# GD32F5HC register map
File version: 1.0
CPU: CM33 r0p4, little endian, MPU, FPU, 4 interrupt priority bits
Registers are 32-bit, read-write, reset 0x0 unless marked. A register's access mark holds for its fields unless they carry their own. Offsets are from the block's base; [hi:lo] are bit positions; {n}, {i} and the like mark numbered series.

## SQPI — Serial/Quad Parallel Interface
Base 0x40025400
Same registers: SEC_SQPI 0x50025400
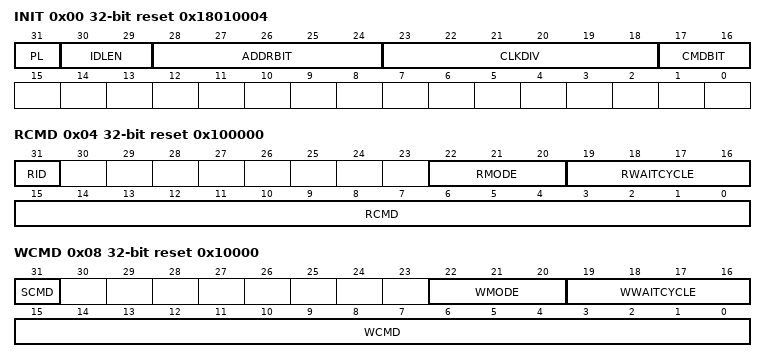
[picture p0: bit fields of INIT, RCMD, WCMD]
0x00 INIT reset 0x18010004 — SQPI Initial Register
  [31] PL — Read data sample polarity.
  [30:29] IDLEN — SQPI controller external memory ID length
  [28:24] ADDRBIT — Bit number of SPI PSRAM address phase.
  [23:18] CLKDIV — Clock divider for SQPI output clock
  [17:16] CMDBIT — Bit number of SQPI controller command phase
0x04 RCMD reset 0x100000 — SQPI Read Command Register
  [31] RID — Send read ID command
  [22:20] RMODE — SQPI controller read command mode
  [19:16] RWAITCYCLE — SQPI read command waitcycle number after address phase
  [15:0] RCMD — SQPI read command for AHB read transfer
0x08 WCMD reset 0x10000 — Write Command Register
  [31] SCMD — Send special command
  [22:20] WMODE — SQPI controller write command mode
  [19:16] WWAITCYCLE — SQPI write command waitcycle number after address phase
  [15:0] WCMD — SQPI write command for AHB write transfer
0x0C IDL ro — ID Low Register
  [31:0] IDL — ID Low Data saved for SQPI Read ID Command
0x10 IDH ro — ID High Register
  [31:0] IDH — ID High Data saved for SQPI read ID command

## SYSCFG — System configuration controller
Base 0x40013800
Same registers: SEC_SYSCFG 0x50013800
0x00 CFG0 — Configuration register 0
  [1:0] BOOT_MODE
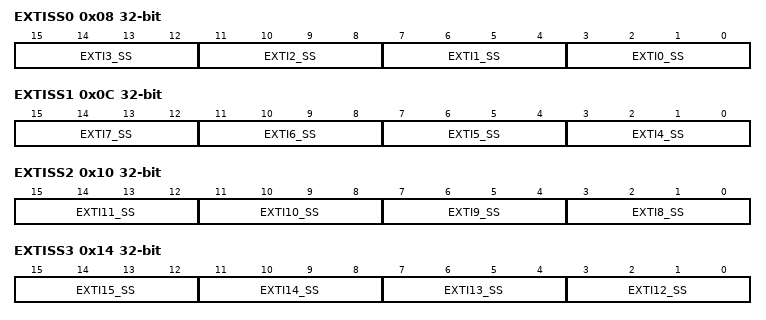
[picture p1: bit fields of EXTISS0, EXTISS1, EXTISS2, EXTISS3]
0x08 EXTISS0 — EXTI sources selection register 0
  [4n+3:4n] EXTI{n}_SS (n=0..3) — EXTI {n} sources selection
0x0C EXTISS1 — EXTI sources selection register 1
  [4n-13:4n-16] EXTI{n}_SS (n=4..7) — EXTI {n} sources selection
0x10 EXTISS2 — EXTI sources selection register 2
  [4n-29:4n-32] EXTI{n}_SS (n=8..11) — EXTI {n} sources selection
0x14 EXTISS3 — EXTI sources selection register 3
  [4n-45:4n-48] EXTI{n}_SS (n=12..15) — EXTI {n} sources selection
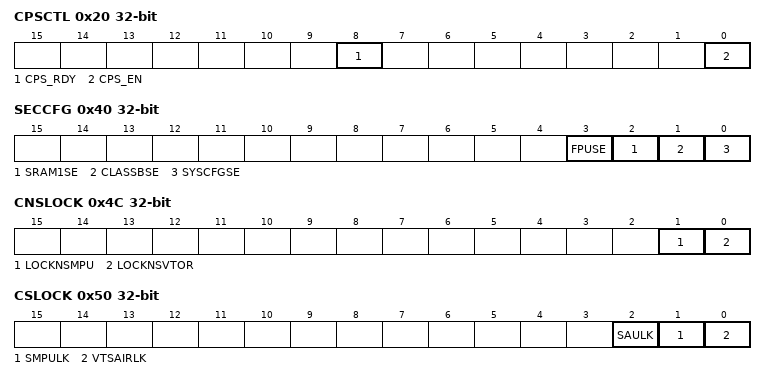
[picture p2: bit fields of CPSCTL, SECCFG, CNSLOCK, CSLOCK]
0x20 CPSCTL access per field — I/O compensation control register
  [8] CPS_RDY ro — I/O compensation cell is ready or not
  [0] CPS_EN rw — I/O compensation cell enable
0x40 SECCFG — SYSCFG secure configuration register
  [3] FPUSE — FPU security
  [2] SRAM1SE — SRAM1 security
  [1] CLASSBSE — ClassB security
  [0] SYSCFGSE — SYSCFG clock control security
0x48 FPUINTMSK reset 0x1F — FPU interrupt mask register
  [5:0] FPU_IE — Floating point unit interrupts enable bits
0x4C CNSLOCK — SYSCFG CPU non-secure lock register
  [1] LOCKNSMPU — Non-secure MPU registers lock
  [0] LOCKNSVTOR — VTOR_NS register lock
0x50 CSLOCK — SYSCFG CPU secure lock register
  [2] SAULK — SAU registers lock
  [1] SMPULK — Secure MPU registers lock
  [0] VTSAIRLK — VTOR_S register and AIRCR register bits lock
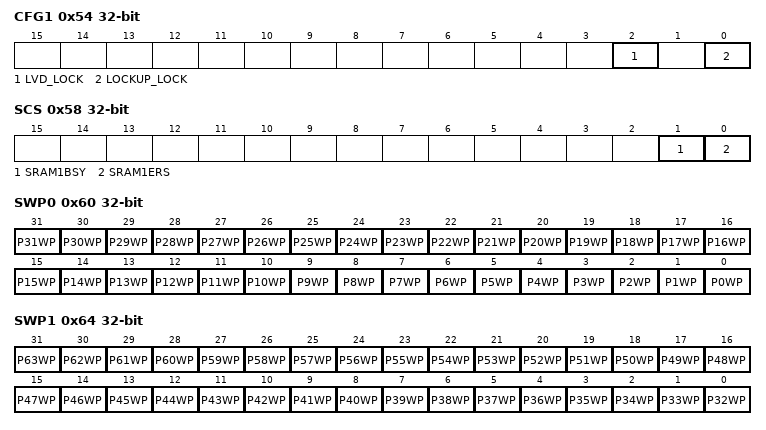
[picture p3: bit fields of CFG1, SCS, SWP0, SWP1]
0x54 CFG1 — SYSCFG configuration register 1
  [2] LVD_LOCK — LVD lock enable bit
  [0] LOCKUP_LOCK — Cortex M33 LOCKUP (hardfault) output enable bit
0x58 SCS access per field — SYSCFG SRAM1 control and status register
  [1] SRAM1BSY ro — SRAM1 busy by erase operation
  [0] SRAM1ERS rw — SRAM1 erase
0x5C SKEY wo — SYSCFG SRAM1 key register
  [7:0] KEY — SRAM1 write protection key for software erase
0x60 SWP0 — SYSCFG SRAM1 write protection register 0
  [n] P{n}WP (n=0..31) — SRAM1 1 Kbyte page {n} write protection
0x64 SWP1 — SYSCFG SRAM1 write protection register 1
  [n-32] P{n}WP (n=32..63) — SRAM1 1 Kbyte page {n} write protection
0x6C GSSACMD — SYSCFG GSSA command register
  [7:0] GSSACMD — GSSA commands
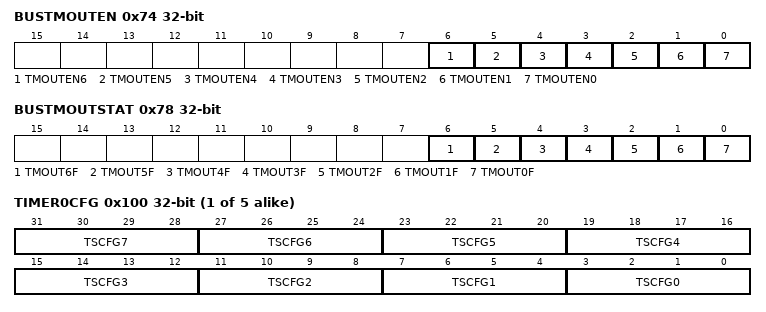
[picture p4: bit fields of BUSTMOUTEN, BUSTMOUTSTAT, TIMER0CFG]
0x74 BUSTMOUTEN — Bus timeout enable register
  [6] TMOUTEN6 — Bus timeout detection enable for DMA1P
  [5] TMOUTEN5 — Bus timeout detection enable for DMA0P
  [4] TMOUTEN4 — Bus timeout detection enable for DMA1M
  [3] TMOUTEN3 — Bus timeout detection enable for DMA0M
  [2] TMOUTEN2 — Bus timeout detection enable for SBUS
  [1] TMOUTEN1 — Bus timeout detection enable for F-C BUS
  [0] TMOUTEN0 — Bus timeout detection enable for S-C BUS
0x78 BUSTMOUTSTAT — Bus timeout status register
  [6] TMOUT6F — Bus timeout detection flag for DMA1P
  [5] TMOUT5F — Bus timeout detection flag for DMA0P
  [4] TMOUT4F — Bus timeout detection flag for DMA1M
  [3] TMOUT3F — Bus timeout detection flag for DMA0M
  [2] TMOUT2F — Bus timeout detection flag for SBUS
  [1] TMOUT1F — Bus timeout detection flag for F-C BUS
  [0] TMOUT0F — Bus timeout detection flag for S-C BUS
{0x100+4i} TIMER{i}CFG (i=0..4) — TIMER{i} configuration register
  [31:28] TSCFG7 — Internal trigger input source configuration
  [27:24] TSCFG6 — External clock mode 0 configuration
  [23:20] TSCFG5 — Event mode configuration
  [19:16] TSCFG4 — Pause mode configuration
  [15:12] TSCFG3 — Restart mode configuration
  [11:8] TSCFG2 — Quadrature decoder mode 2 configuration
  [7:4] TSCFG1 — Quadrature decoder mode 1 configuration
  [3:0] TSCFG0 — Quadrature decoder mode 0 configuration
